# DSS_DSI0_DSI_TOP_VBUSP_CFG_DSI_0_DSI register map
Vendor: Texas Instruments
Registers are 32-bit, read-write, reset 0x0 unless marked. A register's access mark holds for its fields unless they carry their own. Offsets are as the file gives them; [hi:lo] are bit positions; {n}, {i} and the like mark numbered series.

## DSS_DSI0_DSI_TOP_VBUSP_CFG_DSI_0_DSI (part 2 of 2)
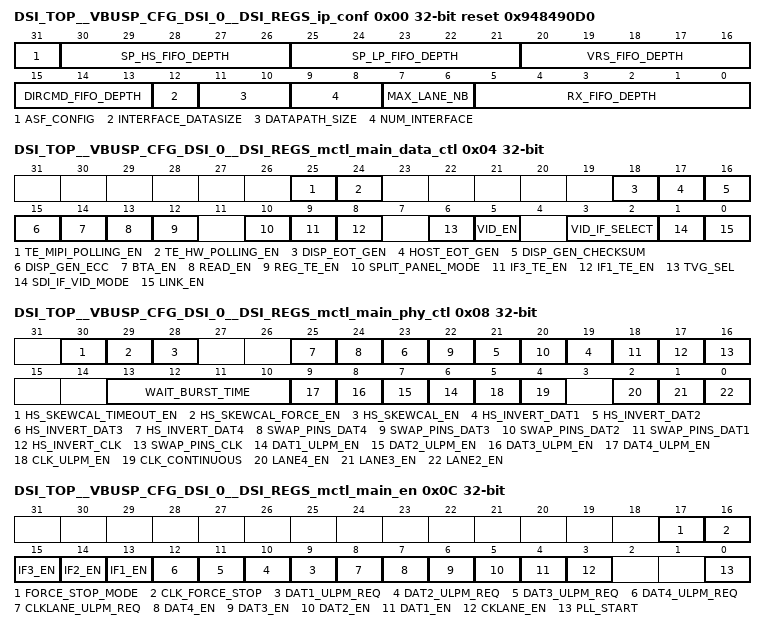
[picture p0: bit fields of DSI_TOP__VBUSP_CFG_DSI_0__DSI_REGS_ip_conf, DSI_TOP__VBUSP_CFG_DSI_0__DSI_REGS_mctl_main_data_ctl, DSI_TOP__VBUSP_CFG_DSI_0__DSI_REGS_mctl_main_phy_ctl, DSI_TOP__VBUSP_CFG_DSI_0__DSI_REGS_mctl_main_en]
0x00 DSI_TOP__VBUSP_CFG_DSI_0__DSI_REGS_ip_conf ro reset 0x948490D0 — IP Configuration for Controller
  [31] ASF_CONFIG — Active Safety Features [ASF] Configuration: 0 = None; 1 = Full ASF.
  [30:26] SP_HS_FIFO_DEPTH — SP_HS_FIFO_DEPTH : HS FIFO depth in sending path.
  [25:21] SP_LP_FIFO_DEPTH — SP_LP_FIFO_DEPTH : LP FIFO depth in sending path.
  [20:16] VRS_FIFO_DEPTH — VRS_FIFO_DEPTH : FIFO depth in the VRS block.
  [15:13] DIRCMD_FIFO_DEPTH — Direct Command FIFO Depth [2:0]. Depth in bytes = 2^[value+2]
  [12] INTERFACE_DATASIZE — SDI interface data width: 0 = 16 bit, 1 = 32bit
  [11:10] DATAPATH_SIZE — Internal Datapath.width 00 - 32 bit, 01 - 16bit, 11 - 8 Bits.
  [9:8] NUM_INTERFACE — Max Number of SDI interfaces [1-4] = [value+1]
  [7:6] MAX_LANE_NB — Max Number of Lanes [1-4] = [value+1]
  [5:0] RX_FIFO_DEPTH — RX FIFO Depth [5:0]
0x04 DSI_TOP__VBUSP_CFG_DSI_0__DSI_REGS_mctl_main_data_ctl — Main Control - main control setting for datapath
  [25] TE_MIPI_POLLING_EN — TE_MIPI_POLLING_EN: enables TE Polling feature following MIPI recommendations [polling by software]
  [24] TE_HW_POLLING_EN — TE_HW_POLLING_EN: enables TE Polling feature following internal solution
  [18] DISP_EOT_GEN — DISP_EOT_GEN: display adds an EOT packet to its LPDT transfers
  [17] HOST_EOT_GEN — HOST_EOT_GEN: generates or not the EOT packet after a transfer in HS.
  [16] DISP_GEN_CHECKSUM — DISP_GEN_CHECKSUM: display generates checksum on its response packets.
  [15] DISP_GEN_ECC — DISP_GEN_ECC: display generates ECC on its response packets
  [14] BTA_EN — BTA_EN: enables BTA
  [13] READ_EN — READ_EN: enables read operation
  [12] REG_TE_EN — REG_TE_EN: enables Tearing Effect from register
  [10] SPLIT_PANEL_MODE — SPLIT_PANEL_MODE: when enabled, DSC stage controls data for split panel signle DPHY link
  [9] IF3_TE_EN — IF3_TE_EN: enables Tearing Effect on interface 3. Note TE on all SDI interfaces is not supported and should be avoided
  [8] IF1_TE_EN — IF1_TE_EN: enables Tearing Effect on interface 1. Note TE on all SDI interfaces is not supported and should be avoided
  [6] TVG_SEL — TVG_SEL: Test Video Generator is enabled [it is not the start signal!] - should not be set if if1_en = 1 and if1_mode = 1 [see MCTL_MAIN_EN register ]
  [5] VID_EN — VID_EN: enables the video stream generator
  [3:2] VID_IF_SELECT — VID_IF_SELECT: Determines which video interface is active [00 : SDI , 01 : DPI, 10 : DSC]
  [1] SDI_IF_VID_MODE — SDI_IF_VID_MODE:1: selected interface is in video mode, 0: selected interface is in command mode]
  [0] LINK_EN — LINK_EN: enables [or not] the link]
0x08 DSI_TOP__VBUSP_CFG_DSI_0__DSI_REGS_mctl_main_phy_ctl — Main control setting for the physical lanes and drive the static signals for D-PHY clock lane
  [30] HS_SKEWCAL_TIMEOUT_EN — HS_SKEWCAL_TIMEOUT_EN: Activate the HS SkewCal Control to occur after a timeout.
  [29] HS_SKEWCAL_FORCE_EN — HS_SKEWCAL_FORCE_EN: Force the HS SkewCal Control to occur immediately
  [28] HS_SKEWCAL_EN — HS_SKEWCAL_EN: activate the HS SkewCal Control at start of HS Transmission
  [2n+17] HS_INVERT_DAT{n} (n=1..4) — HS_INVERT_DAT{n}: invert HS signal on data lane {n}
  [24] SWAP_PINS_DAT4 — SWAP_PINS_DAT4: swap pins on clock lane 4
  [22] SWAP_PINS_DAT3 — SWAP_PINS_DAT3: swap pins on clock lane 3
  [20] SWAP_PINS_DAT2 — SWAP_PINS_DAT2: swap pins on clock lane 2
  [18] SWAP_PINS_DAT1 — SWAP_PINS_DAT1: swap pins on data lane 1
  [17] HS_INVERT_CLK — HS_INVERT_CLK: invert HS signal on clock lane
  [16] SWAP_PINS_CLK — SWAP_PINS_CLK: swap pins on clock lane
  [13:10] WAIT_BURST_TIME — WAIT_BURST_TIME: delay to respect between two HS bursts. Value 0 is forbidden
  [n+5] DAT{n}_ULPM_EN (n=1..4) — DAT{n}_ULPM_EN: data lane {n} can be switched in ULP mode
  [5] CLK_ULPM_EN — CLK_ULPM_EN: specifies that clock lane can be switched in ULP mode [on demand]
  [4] CLK_CONTINUOUS — CLK_CONTINUOUS: clock lane should remain in HS sending mode [no return in STOP state]
  [2] LANE4_EN — LANE4_EN: enables the fourth lane [ controls DCB FSM]
  [1] LANE3_EN — LANE3_EN: enables the third lane [ controls DCB FSM]
  [0] LANE2_EN — LANE2_EN: enables the second lane [ controls DCB FSM]
0x0C DSI_TOP__VBUSP_CFG_DSI_0__DSI_REGS_mctl_main_en — Control start/stop of the DSI link
  [17] FORCE_STOP_MODE — FORCE_STOP_MODE: when enabled, data lanes are forced back in STOP mode - this value should remain asserted for 10 us minimum
  [16] CLK_FORCE_STOP — CLK_FORCE_STOP : force clock lanes back in STOP mode - this value should remain asserted for 10 us minimum
  [15] IF3_EN — IF3_EN: enables DSC interface [i.e. removes stall signal]
  [14] IF2_EN — IF2_EN: enables DPI interface [i.e. removes stall signal]
  [13] IF1_EN — IF1_EN: enables SDI interface [i.e. removes stall signal]
  [n+8] DAT{n}_ULPM_REQ (n=1..4) — DAT{n}_ULPM_REQ: switches data lane {n} in ULP mode
  [8] CLKLANE_ULPM_REQ — CLKLANE_ULPM_REQ: switches clock lane in ULP mode
  [7] DAT4_EN — DAT4_EN: 1: starts data lane 4 [FSM data lane 4 is stuck in start mode if 0]
  [6] DAT3_EN — DAT3_EN: 1: starts data lane 3 [FSM data lane 3 is stuck in start mode if 0]
  [5] DAT2_EN — DAT2_EN: 1: starts data lane 2 [FSM data lane 2 is stuck in start mode if 0]
  [4] DAT1_EN — DAT1_EN: 1: starts data lane 1 [FSM data lane 1 is stuck in start mode if 0]
  [3] CKLANE_EN — CKLANE_EN: 1: starts the clock lane
  [0] PLL_START — PLL_START: enables the PLL [when set, the PLL is started]
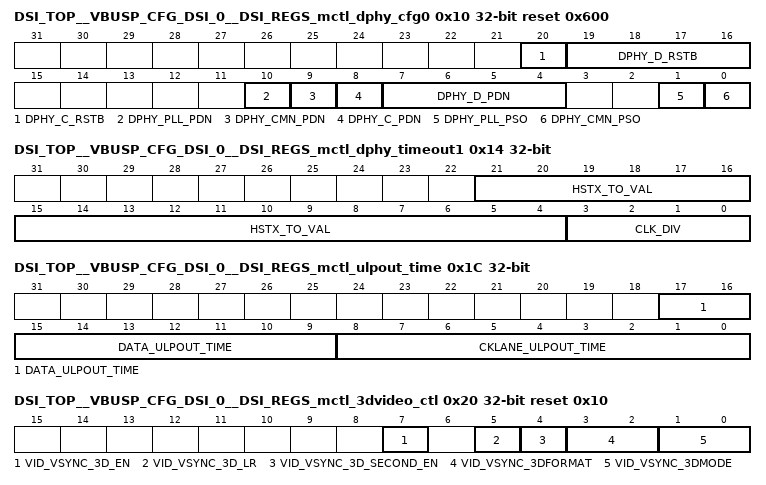
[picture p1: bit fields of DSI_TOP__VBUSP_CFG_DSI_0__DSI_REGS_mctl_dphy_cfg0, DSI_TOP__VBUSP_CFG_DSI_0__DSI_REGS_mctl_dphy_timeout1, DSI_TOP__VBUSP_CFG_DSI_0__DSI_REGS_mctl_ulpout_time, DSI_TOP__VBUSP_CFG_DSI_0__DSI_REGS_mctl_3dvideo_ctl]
0x10 DSI_TOP__VBUSP_CFG_DSI_0__DSI_REGS_mctl_dphy_cfg0 reset 0x600 — DPHY Power and Reset Control
  [20] DPHY_C_RSTB — Drives dphy_c_rstb output
  [19:16] DPHY_D_RSTB — Drives dphy_d_rstb output
  [10] DPHY_PLL_PDN — Drives dphy_pll_pdn output
  [9] DPHY_CMN_PDN — Drives dphy_cmn_pdn output
  [8] DPHY_C_PDN — Drives dphy_c_pdn output
  [7:4] DPHY_D_PDN — Drives dphy_d_pdn output
  [1] DPHY_PLL_PSO — Drives dphy_pll_pso output
  [0] DPHY_CMN_PSO — Drives dphy_cmn_pso output
0x14 DSI_TOP__VBUSP_CFG_DSI_0__DSI_REGS_mctl_dphy_timeout1 — Main DPHY time-out settings. To better understand the way this register is used, please refer to Section : DSI checks (DC) - the counters are based on tx_byte_hs_clk and NOT on sys_clk
  [21:4] HSTX_TO_VAL — HSTX_TO_VAL: HS TX time-out detection value
  [3:0] CLK_DIV — CLK_DIV: clock division ratio
0x18 DSI_TOP__VBUSP_CFG_DSI_0__DSI_REGS_mctl_dphy_timeout2 — To better understand the way this register is used, please refer to Section : DSI checks (DC) - the counters are on tx_byte_hs_clk and not on sys_clk
  [17:0] LPRX_TO_VAL — LPRX_TO_VAL: LP RX time-out detection value
0x1C DSI_TOP__VBUSP_CFG_DSI_0__DSI_REGS_mctl_ulpout_time — Specify time to leave ULP mode. The time-out is reached when the ulpout counter reaches 1000x xxx_ulpout_time and is based upon the system clock
  [17:9] DATA_ULPOUT_TIME — DATA_ULPOUT_TIME: specify what the duration is to leave ULP mode is [for data lane[s] in system clock cycles
  [8:0] CKLANE_ULPOUT_TIME — CKLANE_ULPOUT_TIME: specify what the duration is to leave ULP mode is [for clock lane] in system clock cycles
0x20 DSI_TOP__VBUSP_CFG_DSI_0__DSI_REGS_mctl_3dvideo_ctl reset 0x10 — 3D Video mode stream control
  [7] VID_VSYNC_3D_EN — VID_VSYNC_3D_EN: Enable 3D Control this selects the 3D operation for VSYNC and video data control
  [5] VID_VSYNC_3D_LR — VID_VSYNC_3D_LR: When 3D mode is enabled, this allows to choose which field to start the video stream '0' - Data is sent Left first then right '1' - Data is sent Right first then left
  [4] VID_VSYNC_3D_SECOND_EN — VID_VSYNC_3D_SECOND_EN: When 3D mode is enabled, this allows to choose if a second VSYNC is enabled between L and R images '0' - No sync pulses between left and right data '1' - Sync pulse [HSYNC, VSYNC, Blanking] between left and right image data
  [3:2] VID_VSYNC_3DFORMAT — VID_VSYNC_3DFORMAT: video 3D Format for VSYNC Control Parameter1 '00' - Line Format, alternating line of left and right data '01' - Frame Format, alternating frames of left and right data '10' - Pixel Format, alternating pixels of left and right data '11' - Reserved
  [1:0] VID_VSYNC_3DMODE — VID_VSYNC_3DMODE: video 3D mode for VSYNC Control Parameter1 '00' - 3D mode Off - 2D Mode only '01' - 3D On - Portrait Orientation '10' - 3D On - Landscape Orientation '11' - Reserved
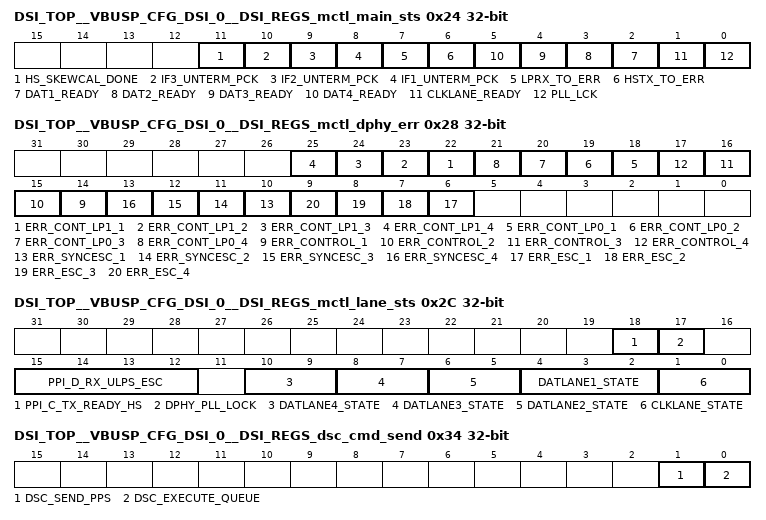
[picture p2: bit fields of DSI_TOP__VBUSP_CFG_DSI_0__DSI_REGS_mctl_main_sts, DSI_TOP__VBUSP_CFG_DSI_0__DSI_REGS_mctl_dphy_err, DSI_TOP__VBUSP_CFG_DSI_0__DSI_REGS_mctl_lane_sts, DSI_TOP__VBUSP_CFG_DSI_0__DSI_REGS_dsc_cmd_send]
0x24 DSI_TOP__VBUSP_CFG_DSI_0__DSI_REGS_mctl_main_sts ro — Status of the DSI link
  [11] HS_SKEWCAL_DONE — HS_SKEWCAL_DONE: HS SkewCal Control Done at start of HS Transmission
  [10] IF3_UNTERM_PCK — IF3_UNTERM_PCK: Indicates an unterminated packet on DSC interface
  [9] IF2_UNTERM_PCK — IF2_UNTERM_PCK: Indicates an unterminated packet on DPI interface
  [8] IF1_UNTERM_PCK — IF1_UNTERM_PCK: Indicates an unterminated packet on SDI Interface
  [7] LPRX_TO_ERR — LPRX_TO_ERR: Indicates an LP_RX time-out error
  [6] HSTX_TO_ERR — HSTX_TO_ERR: Indicates an HS_TX time-out error
  [n+1] DAT{n}_READY (n=1..4) — DAT{n}_READY: Indicates data lane {n} is ready
  [1] CLKLANE_READY — CLKLANE_READY: Indicates the clock lane is ready [normal DSI operation can start]
  [0] PLL_LCK — PLL_LCK: Indicates PLL is locked - data coming from DCB [if DSI link is PLL initiator] or copy of pll_en [if DSI link is target]
0x28 DSI_TOP__VBUSP_CFG_DSI_0__DSI_REGS_mctl_dphy_err ro — Errors reported from DPHY lanes - See description in DPHY inputs and outputs
  [n+21] ERR_CONT_LP1_{n} (n=1..4), [n+17] ERR_CONT_LP0_{n} (n=1..4), [n+13] ERR_CONTROL_{n} (n=1..4), [n+9] ERR_SYNCESC_{n} (n=1..4), [n+5] ERR_ESC_{n} (n=1..4)
0x2C DSI_TOP__VBUSP_CFG_DSI_0__DSI_REGS_mctl_lane_sts ro — DPHY Lane and PLL status information
  [18] PPI_C_TX_READY_HS — Value of ppi_c_tx_ready_hs input
  [17] DPHY_PLL_LOCK — Value of dphy_pll_lock input
  [15:12] PPI_D_RX_ULPS_ESC — Value of ppi_d_rx_ulps_esc input
  [10:9] DATLANE4_STATE — DATLANE4_STATE: state of the data lane 4 [00: start / 01: idle / 10: write / 11: ULPM]
  [8:7] DATLANE3_STATE — DATLANE3_STATE: state of the data lane 3 [00: start / 01: idle / 10: write / 11: ULPM]
  [6:5] DATLANE2_STATE — DATLANE2_STATE: state of the data lane 2 [00: start / 01: idle / 10: write / 11: ULPM]
  [4:2] DATLANE1_STATE — DATLANE1_STATE: state of the data lane 1 [000: start / 001: idle / 010: write / 011: ULPM / 100: read]
  [1:0] CLKLANE_STATE — CLKLANE_STATE: state of the clock lane [00: start / 01: idle / 10: HS / 11: ULPM]
0x30 DSI_TOP__VBUSP_CFG_DSI_0__DSI_REGS_dsc_mode_ctl — DSC Mode Control register
  [0] DSC_MODE_EN — Enable DSC Mode Controls
0x34 DSI_TOP__VBUSP_CFG_DSI_0__DSI_REGS_dsc_cmd_send wo — DSC Command Control register. Write one to perform PPS set transfer or Execute Queue commands
  [1] DSC_SEND_PPS — Send PPS Command and Payload to the display
  [0] DSC_EXECUTE_QUEUE — Send Execute Queue Command to Synchonise the display drivers
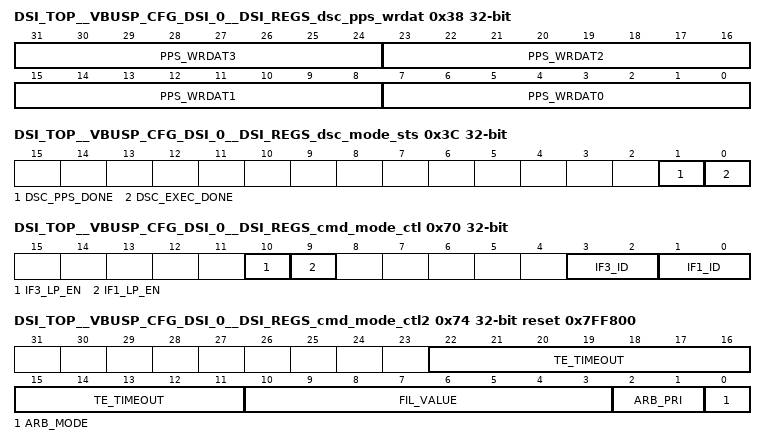
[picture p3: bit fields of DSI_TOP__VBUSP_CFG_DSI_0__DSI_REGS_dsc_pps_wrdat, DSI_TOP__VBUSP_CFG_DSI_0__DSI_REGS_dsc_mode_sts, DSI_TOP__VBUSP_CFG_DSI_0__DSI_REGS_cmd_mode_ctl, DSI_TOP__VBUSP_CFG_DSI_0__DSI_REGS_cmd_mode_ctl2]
0x38 DSI_TOP__VBUSP_CFG_DSI_0__DSI_REGS_dsc_pps_wrdat — DSC PPS Write data to outgoing FIFO Buffer, byte 0 to 3; applicable to either Write or Read commands. Note that any writes to this register that exceed the programmed command payload size or the configured FIFO depth (whichever is smaller) will be ignored. Conversely, if the writes to this register are less than the programmed command payload size when the instruction to send the payload is given, the command payload will contain data from the previous contents of the FIFO for all unwritten bytes, and will therefore be corrupt.
  [31:24] PPS_WRDAT3 — WRDAT3: 4th byte to be sent as part of PPS payload [stored in a FIFO]
  [23:16] PPS_WRDAT2 — WRDAT2: 3rd byte to be sent as part of PPS payload [stored in a FIFO]
  [15:8] PPS_WRDAT1 — WRDAT1: 2nd byte to be sent as part of PPS payload [stored in a FIFO]
  [7:0] PPS_WRDAT0 — WRDAT0: 1st byte to be sent as part of PPS payload [stored in a FIFO]
0x3C DSI_TOP__VBUSP_CFG_DSI_0__DSI_REGS_dsc_mode_sts ro — DSC Event Status Register
  [1] DSC_PPS_DONE — DSC PPS Command Sent
  [0] DSC_EXEC_DONE — DSC Execute Command Sent
0x40 DSI_TOP__VBUSP_CFG_DSI_0__DSI_REGS_mctl_dphy_skewcal_timeout — Used in conjunction with HS_SKEWCAL_TIMEOUT_EN from MCTL_MAIN_PHY_CTL to control periodic skew calibration
  [31:0] SKEWCAL_TO_VAL — SKEWCAL_TO_VAL: Timeout value
0x70 DSI_TOP__VBUSP_CFG_DSI_0__DSI_REGS_cmd_mode_ctl — Command mode control
  [10] IF3_LP_EN — IF3_LP_EN: enable to send command from DSC interface in LP if possible
  [9] IF1_LP_EN — IF1_LP_EN: enable to send command from SDI interface in LP if possible
  [3:2] IF3_ID — IF3_ID: Virtual Channel ID of request from DSC interface command
  [1:0] IF1_ID — IF1_ID: Virtual Channel ID of request from SDI interface command
0x74 DSI_TOP__VBUSP_CFG_DSI_0__DSI_REGS_cmd_mode_ctl2 reset 0x7FF800 — Command mode control
  [22:11] TE_TIMEOUT — TE_TIMEOUT : on TE request - length of TE response window before timeout.
  [10:3] FIL_VALUE — FIL_VALUE: value to use to fill packet during data underrun or to complete unterminated packet [referred as padding value]
  [2:1] ARB_PRI — ARB_PRI: in fixed mode, specify interface with higher priority SDI 01, DSC 10
  [0] ARB_MODE — ARB_MODE: arbitration mode [1: round robin, 0: fixed]
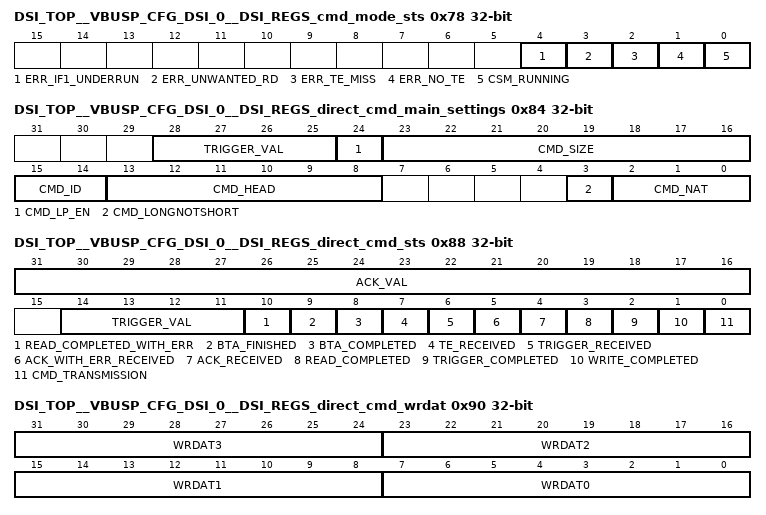
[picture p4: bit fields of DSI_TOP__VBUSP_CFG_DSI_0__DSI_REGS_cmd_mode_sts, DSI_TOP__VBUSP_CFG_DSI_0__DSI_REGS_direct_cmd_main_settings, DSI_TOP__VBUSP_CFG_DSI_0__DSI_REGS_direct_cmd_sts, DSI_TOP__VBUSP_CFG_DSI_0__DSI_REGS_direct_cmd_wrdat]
0x78 DSI_TOP__VBUSP_CFG_DSI_0__DSI_REGS_cmd_mode_sts ro — Command Mode status
  [4] ERR_IF1_UNDERRUN — ERR_IF1_UNDERRUN: Indicates a data shortage occurs on IF1
  [3] ERR_UNWANTED_RD — ERR_UNWANTED_RD: Indicates a read request was received while read capability was not enabled
  [2] ERR_TE_MISS — ERR_TE_MISS: error: TE window time-out
  [1] ERR_NO_TE — ERR_NO_TE: error: no TE generated by display
  [0] CSM_RUNNING — CSM_RUNNING: Indicates CSM is running - command[s] are being proceeded
0x80 DSI_TOP__VBUSP_CFG_DSI_0__DSI_REGS_direct_cmd_send wo — Direct_cmd_send is not a real register. When this address is written (whatever its value is), it signals to the link that a direct command has to be sent. It is then a write only register.No specific mechanism is implemented to prevent the application sending two direct commands back-to-back. It is then applications responsibility to verify the completion of a first direct command before starting another direct command.Interlacing of command or video with direct command is managed by the DSI link using the different arbiters (see Command and register arbiter (CRA) and Video/command arbiter (VCA))
  [31:0] DIRECT_CMD_SEND — Initiate the direct command send operation
0x84 DSI_TOP__VBUSP_CFG_DSI_0__DSI_REGS_direct_cmd_main_settings — Main control of the Direct Command function.
  [28:25] TRIGGER_VAL — TRIGGER_VAL: trigger value if trigger request [see Note about trigger mapping] - signal is one hot encoding [only one bit out of the 4 should be set to 1].
  [24] CMD_LP_EN — CMD_LP_EN: enables LP sending for the command request
  [23:16] CMD_SIZE — CMD_SIZE: size, in bytes, of the command payload. Note that the value written here by software should comply with certain limits. For write operations, any value written which is larger than the FIFO depth [direct_cmd_fifodepth parameter] will be ignored and the command payload will be truncated to the maximum FIFO depth. For read operations, any value written which is larger than 2 bytes will be ignored and the command payload will be truncated to 2 bytes.
  [15:14] CMD_ID — CMD_ID: For a read/write command, Virtual Channel of the command
  [13:8] CMD_HEAD — CMD_HEAD: For a read/write command, datatype of the command
  [3] CMD_LONGNOTSHORT — CMD_LONGNOTSHORT: Tie this to '1' if a long packet has to be generated.
  [2:0] CMD_NAT — CMD_NAT: Type of the direct command: 000: write command 001: read command 100: TE request 101: trigger request 110: BTA request
0x88 DSI_TOP__VBUSP_CFG_DSI_0__DSI_REGS_direct_cmd_sts ro — Direct Command Status: To ensure that the observed status bits are coherent and applicable to the last command message sent, it is recommended to clear this register between accesses by writing to direct_cmd_clr, otherwise the status of the different commands is logically ORed, making it difficult to differentiate between the status of each message.
  [31:16] ACK_VAL — ACK_VAL: if an acknowledge with error has been received, this field reports its value
  [14:11] TRIGGER_VAL — TRIGGER_VAL: if a trigger has been received, this field reports its value - refer to Note regarding trigger mapping
  [10] READ_COMPLETED_WITH_ERR — READ_COMPLETED_WITH_ERR: read command terminated with error
  [9] BTA_FINISHED — BTA_FINISHED: DSI link recovered link initiator role after a BTA request
  [8] BTA_COMPLETED — BTA_COMPLETED: indicates that BTA request completed
  [7] TE_RECEIVED — TE_RECEIVED: TE received
  [6] TRIGGER_RECEIVED — TRIGGER_RECEIVED: If command with BTA, this bit is set if an trigger was received
  [5] ACK_WITH_ERR_RECEIVED — ACKNOWLEDGE_WITH_ERR_RECEIVED: If command with BTA, this bit is set if an acknowledge with error was received
  [4] ACK_RECEIVED — ACKNOWLEDGE_RECEIVED: If command with BTA, this bit is set if an acknowledge with no error was received
  [3] READ_COMPLETED — READ_COMPLETED: read command request completed
  [2] TRIGGER_COMPLETED — TRIGGER_COMPLETED: trigger command request completed
  [1] WRITE_COMPLETED — WRITE_COMPLETED: write command request completed
  [0] CMD_TRANSMISSION — CMD_TRANSMISSION: a command is being sent
0x8C DSI_TOP__VBUSP_CFG_DSI_0__DSI_REGS_direct_cmd_rd_init wo — This register is not a real register - when written it stops the read command process by emptying the FIFO and by stopping the reception of the data (RP does not consider the data that it receives and the system waits for the D-PHY to return to Tx STOP state).
  [31:0] STOP_READ_OPERATION
0x90 DSI_TOP__VBUSP_CFG_DSI_0__DSI_REGS_direct_cmd_wrdat — Write data to outgoing Direct Command FIFO, byte 0 to 3; applicable to either Write or Read commands. Note that any writes to this register that exceed the programmed command payload size or the configured FIFO depth (whichever is smaller) will be ignored. Conversely, if the writes to this register are less than the programmed command payload size when the instruction to send the payload is given, the command payload will contain data from the previous contents of the FIFO for all unwritten bytes, and will therefore be corrupt. Note also that values written to the FIFO which are intended for transmission of single parameter write transaction must set the MS bytes to zero to comply with DSI standard requirements.
  [31:24] WRDAT3 — WRDAT3: 4th byte to be sent as part of Direct Command [stored in a FIFO]
  [23:16] WRDAT2 — WRDAT2: 3rd byte to be sent as part of Direct Command [stored in a FIFO]
  [15:8] WRDAT1 — WRDAT1: 2nd byte to be sent as part of Direct Command [stored in a FIFO]
  [7:0] WRDAT0 — WRDAT0: 1st byte to be sent as part of Direct Command [stored in a FIFO]
0x94 DSI_TOP__VBUSP_CFG_DSI_0__DSI_REGS_direct_cmd_fifo_rst wo — Reset the write FIFO. This register is not a real register - when written it reset the FIFO pointer
  [31:0] CMD_FIFO_RST — Direct Command FIFO Reset
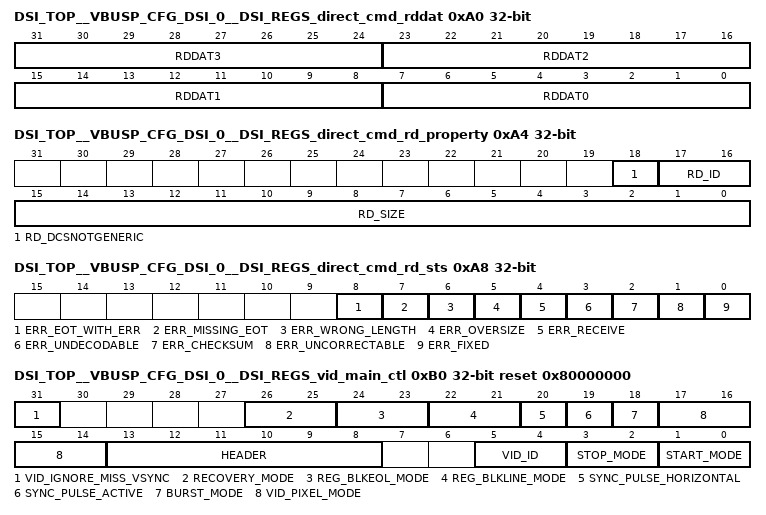
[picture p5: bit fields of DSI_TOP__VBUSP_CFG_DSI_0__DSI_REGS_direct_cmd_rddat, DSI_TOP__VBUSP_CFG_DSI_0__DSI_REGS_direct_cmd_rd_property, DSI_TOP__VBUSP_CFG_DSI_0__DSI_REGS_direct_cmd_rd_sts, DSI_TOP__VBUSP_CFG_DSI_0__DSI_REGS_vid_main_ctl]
0xA0 DSI_TOP__VBUSP_CFG_DSI_0__DSI_REGS_direct_cmd_rddat ro — Data from incoming Direct Command receive path, byte 0 to 3. NOTE: SW must mask any bytes which are in excess of the actual message size (e.g. for a 2-byte message payload, take data from bytes [1:0] and mask off bytes [3:2])
  [31:24] RDDAT3 — RDDAT3: 4th byte from incoming Direct Command receive path
  [23:16] RDDAT2 — RDDAT2: 3rd byte from incoming Direct Command receive path
  [15:8] RDDAT1 — RDDAT1: 2nd byte from incoming Direct Command receive path
  [7:0] RDDAT0 — RDDAT0: 1st byte from incoming Direct Command receive path
0xA4 DSI_TOP__VBUSP_CFG_DSI_0__DSI_REGS_direct_cmd_rd_property ro — read command characteristics
  [18] RD_DCSNOTGENERIC — RD_DCSNOTGENERIC: Type of read command [DCS or generic]
  [17:16] RD_ID — RD_ID: Virtual channel of the read received
  [15:0] RD_SIZE — RD_SIZE: Size of the read data received
0xA8 DSI_TOP__VBUSP_CFG_DSI_0__DSI_REGS_direct_cmd_rd_sts ro — Status of the read command received. It is recommended to clear direct_cmd_sts between two direct commands (at least between 2 read) in order to see coherent status
  [8] ERR_EOT_WITH_ERR — ERR_EOT_WITH_ERR: EOT received with error
  [7] ERR_MISSING_EOT — ERR_MISSING_EOT: EOT requested but not received
  [6] ERR_WRONG_LENGTH — ERR_WRONG_LENGTH : length error has been detected. This error indicates that a packet has been received which was shorter than the expected length [longer packets than expected will result in ERR_RECEIVE field being set, as it is difficult to distinguish the extra information from other types of reception errors].
  [5] ERR_OVERSIZE — ERR_OVERSIZE : packet size exceeds maximum
  [4] ERR_RECEIVE — ERR_RECEIVE : received packet not complete. This is a general error flag indicated that packet reception did not complete for some reason. Example conditions: signalling errors [e.g. unexpected change in PPI direction signal]; longer packet received than expected.
  [3] ERR_UNDECODABLE — ERR_UNDECODABLE : command opcode not understood
  [2] ERR_CHECKSUM — ERR_CHECKSUM: error[s] detected by checksum
  [1] ERR_UNCORRECTABLE — ERR_UNCORRECTABLE : more than 1 error detected by ECC
  [0] ERR_FIXED — ERR_FIXED : one error detected and fixed by ECC
0xB0 DSI_TOP__VBUSP_CFG_DSI_0__DSI_REGS_vid_main_ctl reset 0x80000000 — Video mode main control
  [31] VID_IGNORE_MISS_VSYNC — VID_IGNORE_MISSING_SYNC: When mode is enabled, this allows the video stream to go to IDLE during VFP and wait for new VSYNC without link failing to recovery
  [26:25] RECOVERY_MODE — RECOVERY_MODE: specify recovery mode
  [24:23] REG_BLKEOL_MODE — REG_BLKEOL_MODE: behavior during end of line in burst mode - same coding as reg_blkline_mode
  [22:21] REG_BLKLINE_MODE — REG_BLKLINE_MODE : behavior during blanking time [1x: LP, 01: blanking packet - 00: NULL packet]
  [20] SYNC_PULSE_HORIZONTAL — SYNC_PULSE_HORIZONTAL: syncs are pulse [1] or event [0] all the time [DSI protocol v1.00..._r6 and later] - to be set only when sync_pulse_active = 1
  [19] SYNC_PULSE_ACTIVE — SYNC_PULSE_ACTIVE: syncs are pulse [1] or event [0] during active area [DSI protocol v1.00..._r3 and before]
  [18] BURST_MODE — BURST_MODE: signals if system works in burst mode or not
  [17:14] VID_PIXEL_MODE — VID_PIXEL_MODE: 0000: 16 bits RGB - 0001: 18 bits RGB 0010: 18 bits RGB[loose] - 0011: 24 bits RGB 0100: 30 bits RGB - 0101: 36 bits RGB 1000: 12 bits YCbCr - 1001: 16 bits YCbCr 1010: 20 bits YCbCr - 1011: 24 bits YCbCr 1100: DSC Compressed
  [13:8] HEADER — HEADER : specify the datatype of RGB packets
  [5:4] VID_ID — VID_ID : specify the Virtual Channel Identifier of the video packets
  [3:2] STOP_MODE — STOP_MODE : video stop point [see description in Video Stream Generator [VSG] section] .[The configurations where the frame stops at the end of any line and at the end of the last active line - start_mode in [1;2] - are being deprecated, thus not verified anymore
  [1:0] START_MODE — START_MODE: video entry point [see description in Video Stream Generator [VSG] section][The configuration where the frame starts with a VFP - start_mode=1 - is being deprecated, thus not verified anymore]
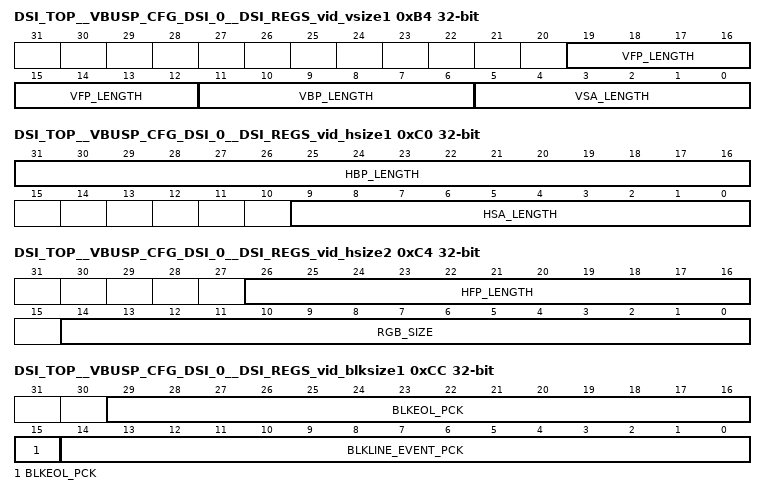
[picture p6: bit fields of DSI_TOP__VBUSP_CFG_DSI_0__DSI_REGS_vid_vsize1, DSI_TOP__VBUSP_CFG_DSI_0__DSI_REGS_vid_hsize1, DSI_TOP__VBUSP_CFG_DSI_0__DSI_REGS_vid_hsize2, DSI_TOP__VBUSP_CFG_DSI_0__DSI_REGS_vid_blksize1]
0xB4 DSI_TOP__VBUSP_CFG_DSI_0__DSI_REGS_vid_vsize1 — Image vertical Sync and Blanking settings
  [19:12] VFP_LENGTH — VFP_LENGTH: length of the VFP [in lines]
  [11:6] VBP_LENGTH — VBP_LENGTH: length of the VBP [in lines]
  [5:0] VSA_LENGTH — VSA_LENGTH: duration of the VSYNC pulse [in lines]
0xB8 DSI_TOP__VBUSP_CFG_DSI_0__DSI_REGS_vid_vsize2 — Image vertical active line setting
  [12:0] VACT_LENGTH — VACT_LENGTH: vertical length of active area [in line]
0xC0 DSI_TOP__VBUSP_CFG_DSI_0__DSI_REGS_vid_hsize1 — Image horizontal sync and Blanking setting Active line Pulse Mode: |____hsync_____|____hbp_____|________________hact_______________|_______hfp________| |_HSS_HSA_HSE__|HDR_HBP_CRC_|HDR_____________HACT____________CRC|HDR____HFP_____CRC|_HSS_ Active line Event Mode: |____hsync_____|____hbp_____|________________hact_______________|_______hfp________| |_HSS_|HDR___HSA+HBP____CRC_|HDR_____________HACT____________CRC|HDR____HFP_____CRC|_HSS_
  [31:16] HBP_LENGTH — HBP_LENGTH: length of HBP [in bytes] - if 0, HBP packet is sent with 0 payload
  [9:0] HSA_LENGTH — HSA_LENGTH: duration of HSYNC pulse [in bytes]
0xC4 DSI_TOP__VBUSP_CFG_DSI_0__DSI_REGS_vid_hsize2 — Image horizontal byte size setting
  [26:16] HFP_LENGTH — HFP_LENGTH: length of HFP [in bytes] - if 0, no HFP packet is sent
  [14:0] RGB_SIZE — RGB_SIZE: size [in byte] of the RGB packet
0xCC DSI_TOP__VBUSP_CFG_DSI_0__DSI_REGS_vid_blksize1 — blanking packet size
  [29:15] BLKEOL_PCK — BLKEOL_PCK: packet length [in byte] on end of line if burst mode [reg_blkeol_mode = 0b0x]
  [14:0] BLKLINE_EVENT_PCK — BLKLINE_EVENT_PCK: packet length [in byte] in blanking line if line has to be filled with a packet [reg_blkline_mode = 0b0x] and sync is an event Event mode Blank line |_____|________________________________blkline_event_pck___________________________| |_HSS_|HDR______________________________________________________________________CRC|_HSS_
0xD0 DSI_TOP__VBUSP_CFG_DSI_0__DSI_REGS_vid_blksize2 — Pulse Mode blanking packet size
  [14:0] BLKLINE_PULSE_PCK — BLKLINE_PULSE_PCK: packet length in blanking line if line has to be filled with a packet [reg_blkline_mode = 0b0x] and sync is a pulse Pulse mode Blank line |_____________ |_______________________blkline_pulse_pck___________________________| |_HSS_HSA_HSE__|HDR_____________________________________________________________CRC|_HSS_
0xD8 DSI_TOP__VBUSP_CFG_DSI_0__DSI_REGS_vid_pck_time — Packet duration
  [14:0] BLKEOL_DURATION — BLKEOL_DURATION: specify the duration in clock cycles of the BLLP period [used for burst mode]
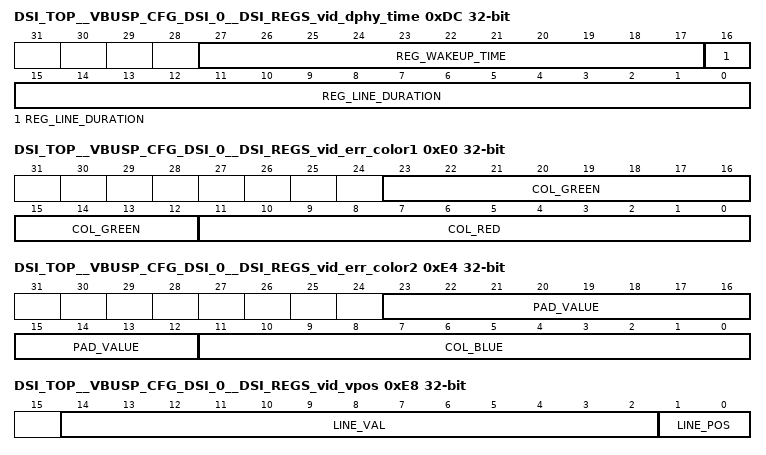
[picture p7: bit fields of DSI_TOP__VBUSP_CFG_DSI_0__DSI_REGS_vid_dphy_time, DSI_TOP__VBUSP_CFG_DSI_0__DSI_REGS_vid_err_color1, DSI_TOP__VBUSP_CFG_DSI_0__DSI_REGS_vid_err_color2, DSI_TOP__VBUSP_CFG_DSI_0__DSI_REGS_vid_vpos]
0xDC DSI_TOP__VBUSP_CFG_DSI_0__DSI_REGS_vid_dphy_time — Time of D-PHY behavior for wakeup time and Line duration for LP during horozontal blanking lines
  [27:17] REG_WAKEUP_TIME — REG_WAKEUP_TIME: estimated time [in clock cycles] to perform LP->HS on D-PHY |___________reg_wakeup_time________________| | Clk Request |------------>| Clk Ready | Data Request |-------------------> | Data Ready
  [16:0] REG_LINE_DURATION — REG_LINE_DURATION: duration -in clock cycles - of the blanking area for VSA/VBP and VFP lines - considered when reg_blkline_mode = 1b1x Pulse mode Blank LP line EOT disabled |_____________ |___________________________reg_line_duration_______________________| |_HSS_HSA_HSE__|______________________________LP___________________________________|_HSS_ Pulse mode Blank LP line EOT enabled |______________| |_______________________reg_line_duration_______________________| |_HSS_HSA_HSE__|EoT|__________________________LP___________________________________|_HSS_ Event mode Blank LP line EOT enabled |________|_________________________________reg_line_duration_______________________| |_HSS|EoT|____________________________________LP___________________________________|_HSS_
0xE0 DSI_TOP__VBUSP_CFG_DSI_0__DSI_REGS_vid_err_color1 — error color (green and red)
  [23:12] COL_GREEN — COL_GREEN: green component of the fill color
  [11:0] COL_RED — COL_RED: red component of the fill color
0xE4 DSI_TOP__VBUSP_CFG_DSI_0__DSI_REGS_vid_err_color2 — error color (blue and padding)
  [23:12] PAD_VALUE — PAD_VALUE: byte used to pad data [when system does not know exactly where it is]
  [11:0] COL_BLUE — COL_BLUE: blue component of the fill color
0xE8 DSI_TOP__VBUSP_CFG_DSI_0__DSI_REGS_vid_vpos ro — vertical position
  [14:2] LINE_VAL — LINE_VAL: line number of the current area
  [1:0] LINE_POS — LINE_POS: position in the frame [see description in Video Stream Generator]
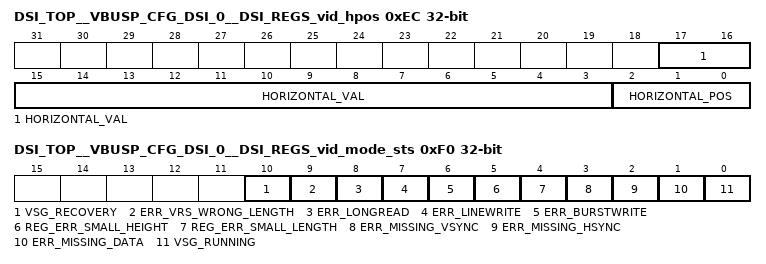
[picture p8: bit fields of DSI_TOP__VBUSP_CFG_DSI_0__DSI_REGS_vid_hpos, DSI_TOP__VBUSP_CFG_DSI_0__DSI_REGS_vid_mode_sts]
0xEC DSI_TOP__VBUSP_CFG_DSI_0__DSI_REGS_vid_hpos ro — Horizontal Position
  [17:3] HORIZONTAL_VAL — HORIZONTAL_VAL: position in the current horizontal area [in clock cycles]
  [2:0] HORIZONTAL_POS — HORIZONTAL_POS: position in the line [see description in Video Stream Generator]
0xF0 DSI_TOP__VBUSP_CFG_DSI_0__DSI_REGS_vid_mode_sts ro — Video mode status and error reporting
  [10] VSG_RECOVERY — VSG_RECOVERY: specifies whether the VSG is in recovery mode or not
  [9] ERR_VRS_WRONG_LENGTH — ERR_VRS_WRONG_LENGTH: signals that packets in SDI interface differ from the expected size [as specified by rgb_size]
  [8] ERR_LONGREAD — ERR_LONGREAD: signals the read was too long
  [7] ERR_LINEWRITE — ERR_LINEWRITE: signals the long packet is too long to pass during a long slot
  [6] ERR_BURSTWRITE — ERR_BURSTWRITE: signals a long packet has been sent during active area
  [5] REG_ERR_SMALL_HEIGHT — REG_ERR_SMALL_HEIGHT: fewer lines than expected between 2 VSYNC
  [4] REG_ERR_SMALL_LENGTH — REG_ERR_SMALL_LENGTH: fewer bytes received than expected between 2 HSYNC. Note that MISSING_DATA error may occur instead of SMALL_LENGTH, dependent upon timing.
  [3] ERR_MISSING_VSYNC — ERR_MISSING_VSYNC: missing VSYNC
  [2] ERR_MISSING_HSYNC — ERR_MISSING_HSYNC: missing HSYNC
  [1] ERR_MISSING_DATA — ERR_MISSING_DATA: data starvation at input of the VSG. Note that this error report may also be triggered instead of the SMALL_LENGTH error, dependent upon timing.
  [0] VSG_RUNNING — VSG_RUNNING: VSG is running [1] or stopped [0]
